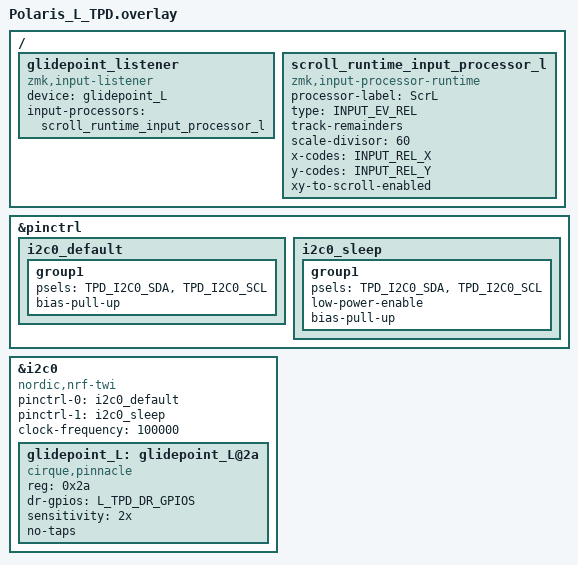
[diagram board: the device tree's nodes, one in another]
#include "Polaris_pins.dtsi"
#include <dt-bindings/zmk/keys.h>
#include <dt-bindings/zmk/pointing.h>

/ {
    glidepoint_listener: glidepoint_listener {
        compatible = "zmk,input-listener";
        status = "okay";
        device = <&glidepoint_L>;
        
        input-processors = <&scroll_runtime_input_processor_l>;
    };
    
	scroll_runtime_input_processor_l: scroll_runtime_input_processor_l {
		compatible = "zmk,input-processor-runtime";
        processor-label = "ScrL";
		type = <INPUT_EV_REL>;
		track-remainders;
		scale-divisor = <60>;
		#input-processor-cells = <0>;
	};   
};

&pinctrl {    
    i2c0_default: i2c0_default {
        group1 {
            psels = <TPD_I2C0_SDA>,
                    <TPD_I2C0_SCL>;
            bias-pull-up;
        };
    };
      
    i2c0_sleep: i2c0_sleep {
        group1 {
            psels = <TPD_I2C0_SDA>,
                    <TPD_I2C0_SCL>;
            low-power-enable;
            bias-pull-up;
        };
    };
};

&i2c0 {
    status = "okay";
    compatible = "nordic,nrf-twi";
    pinctrl-0 = <&i2c0_default>;
    pinctrl-1 = <&i2c0_sleep>;
    pinctrl-names = "default", "sleep";
    clock-frequency = <100000>; 
    
    glidepoint_L: glidepoint_L@2a {
            compatible = "cirque,pinnacle";
            reg = <0x2a>;
            status = "okay";
            dr-gpios = L_TPD_DR_GPIOS;

            sensitivity = "2x";
            // sleep;
            no-taps;
        };
};

&scroll_runtime_input_processor_l {
        x-codes = <INPUT_REL_X>;
        y-codes = <INPUT_REL_Y>;
        xy-to-scroll-enabled;
};
